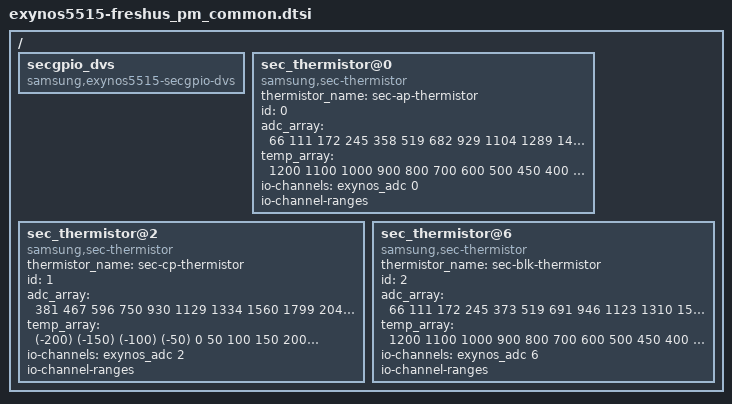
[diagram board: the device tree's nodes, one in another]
/*
 * SAMSUNG EXYNOS5515 Power Management device tree source
 *
 * Copyright (c) 2021 Samsung Electronics Co., Ltd.
 *		http://www.samsung.com
 *
 * This program is free software; you can redistribute it and/or modify
 * it under the terms of the GNU General Public License version 2 as
 * published by the Free Software Foundation.
 */

/ {
	fragment@common {
		target-path = "/";
		__overlay__ {
			secgpio_dvs {
				compatible = "samsung,exynos5515-secgpio-dvs";
				status = "okay";
			};

			sec_thermistor@0 {
				compatible = "samsung,sec-thermistor";
				status = "okay";
				thermistor_name = "sec-ap-thermistor";
				id = <0>;

				adc_array = <66 111 172 245 358 519 682 929 1104
							1289 1495 1735 2143 2633 3050 3416 3664>;
				temp_array = <1200 1100 1000 900 800 700 600 500 450
							400 350 300 200 100 0 (-100) (-200)>;

				io-channels = <&exynos_adc 0>;
				io-channel-names = "adc-ap-temp";
				io-channel-ranges;
			};

			sec_thermistor@2 {
				compatible = "samsung,sec-thermistor";
				status = "okay";
				thermistor_name = "sec-cp-thermistor";
				id = <1>;

				adc_array = <381 467 596 750 930 1129 1334 1560 1799 2047
							2312 2529 2736 2927 3103 3254 3382 3484 3570 3648
							3713 3767 3817>;
				temp_array = <(-200) (-150) (-100) (-50) 0 50 100 150 200 250
							300 350 400 450 500 550 600 650 700 750
							800 850 900>;

				io-channels = <&exynos_adc 2>;
				io-channel-names = "adc-cp-temp";
				io-channel-ranges;
			};

			sec_thermistor@6 {
				compatible = "samsung,sec-thermistor";
				status = "okay";
				thermistor_name = "sec-blk-thermistor";
				id = <2>;

				adc_array = <66 111 172 245 373 519 691 946 1123
							1310 1515 1757 2153 2644 3056 3422 3686 3799 4000>;
				temp_array = <1200 1100 1000 900 800 700 600 500 450
							400 350 300 200 100 0 (-100) (-200) (-300) (-400)>;

				io-channels = <&exynos_adc 6>;
				io-channel-names = "adc-blk-temp";
				io-channel-ranges;
			};
		}; /* end of __overlay__ */
	}; /* end of fragment */
}; /* end of root */
